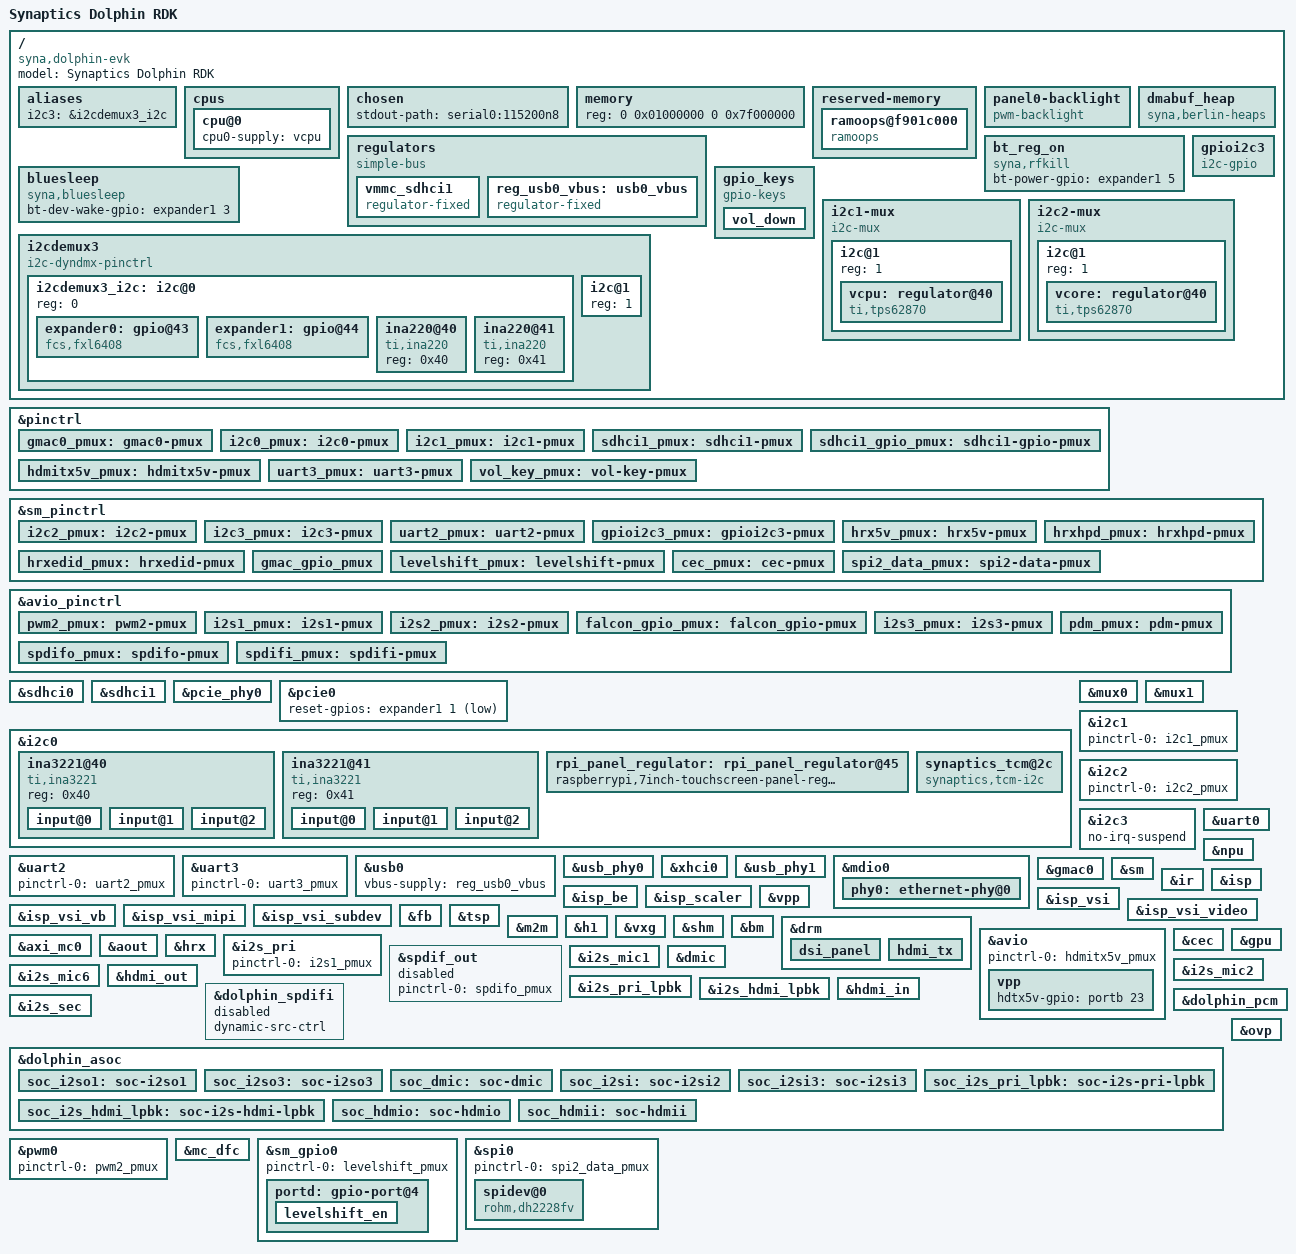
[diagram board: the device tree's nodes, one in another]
/* SPDX-License-Identifier: GPL-2.0+ */
/*
* Copyright (C) 2016~2023 Synaptics Incorporated. All rights reserved.
*
* This program is free software; you can redistribute it and/or modify
* it under the terms of the GNU General Public License version 2 or
* later as published by the Free Software Foundation.
*
* INFORMATION CONTAINED IN THIS DOCUMENT IS PROVIDED "AS-IS," AND
* SYNAPTICS EXPRESSLY DISCLAIMS ALL EXPRESS AND IMPLIED WARRANTIES,
* INCLUDING ANY IMPLIED WARRANTIES OF MERCHANTABILITY AND FITNESS FOR
* A PARTICULAR PURPOSE, AND ANY WARRANTIES OF NON-INFRINGEMENT OF ANY
* INTELLECTUAL PROPERTY RIGHTS. IN NO EVENT SHALL SYNAPTICS BE LIABLE
* FOR ANY DIRECT, INDIRECT, INCIDENTAL, SPECIAL, PUNITIVE, OR
* CONSEQUENTIAL DAMAGES ARISING OUT OF OR IN CONNECTION WITH THE USE
* OF THE INFORMATION CONTAINED IN THIS DOCUMENT, HOWEVER CAUSED AND
* BASED ON ANY THEORY OF LIABILITY, WHETHER IN AN ACTION OF CONTRACT,
* NEGLIGENCE OR OTHER TORTIOUS ACTION, AND EVEN IF SYNAPTICS WAS
* ADVISED OF THE POSSIBILITY OF SUCH DAMAGE. IF A TRIBUNAL OF
* COMPETENT JURISDICTION DOES NOT PERMIT THE DISCLAIMER OF DIRECT
* DAMAGES OR ANY OTHER DAMAGES, SYNAPTICS' TOTAL CUMULATIVE LIABILITY
* TO ANY PARTY SHALL NOT EXCEED ONE HUNDRED U.S. DOLLARS.
*/

/dts-v1/;

/memreserve/ 0x7f000000 0x01000000;

#include <dt-bindings/gpio/gpio.h>
#include <dt-bindings/input/linux-event-codes.h>

#include "dolphin.dtsi"

/ {
	model = "Synaptics Dolphin RDK";
	compatible = "syna,dolphin-evk", "syna,dolphin";

	aliases {
		i2c3 = &i2cdemux3_i2c;
	};

	cpus {
		cpu@0 {
			cpu0-supply = <&vcpu>;
		};
	};

	chosen {
		stdout-path = "serial0:115200n8";
	};

	memory {
		device_type = "memory";
		reg = <0 0x01000000 0 0x7f000000>;
	};

	reserved-memory {
		#address-cells = <2>;
		#size-cells = <2>;
		ranges;

		ramoops@f901c000{
			compatible = "ramoops";
			reg = <0x0 0xf901c000 0x0 0x4000>;
			record-size = <0x4000>;
		};
	};

	panel0-backlight {
		compatible = "pwm-backlight";
		pwms = <&pwm0 1 1000000 0>;
		brightness-levels = <0 4 8 16 32 64 128 255>;
		default-brightness-level = <6>;
		enable-gpio = <&expander0 1 GPIO_ACTIVE_HIGH>;
		status = "okay";
	};

	dmabuf_heap {
		compatible = "syna,berlin-heaps";
		pool-num = <2>;
		reg-names = "NonSecure", "Secure";
		reg = <0 0x7f000000 0 0x00800000>,
		      <0 0x7f800000 0 0x00800000>;
		attributes-num-per-pool = <2>;
		pool-attributes = <0x00000105 0x00000F3A 0x00000102 0x00000F3D>;
	};

	regulators {
		compatible = "simple-bus";
		#address-cells = <1>;
		#size-cells = <0>;

		vmmc_sdhci1: vmmc_sdhci1 {
			compatible = "regulator-fixed";
			regulator-min-microvolt = <3300000>;
			regulator-max-microvolt = <3300000>;
			regulator-name = "vmmc_sdio";
			enable-active-high;
			gpio = <&portb 12 GPIO_ACTIVE_HIGH>;
		};

		reg_usb0_vbus: usb0_vbus {
			compatible = "regulator-fixed";
			regulator-name = "usb0_vbus";
			regulator-min-microvolt = <5000000>;
			regulator-max-microvolt = <5000000>;
			gpio = <&expander0 5 GPIO_ACTIVE_HIGH>;
			enable-active-high;
		};
	};

	bt_reg_on: bt_reg_on {
		compatible = "syna,rfkill";
		bt-power-gpio = <&expander1 5 GPIO_ACTIVE_HIGH>;
	};

	bluesleep: bluesleep {
		compatible = "syna,bluesleep";
		bt-dev-wake-gpio = <&expander1 3 GPIO_ACTIVE_HIGH>;
	};

	gpio_keys {
		compatible = "gpio-keys";
		label = "gpio-keys";
		pinctrl-names = "default";
		pinctrl-0 = <&vol_key_pmux>;

		/* volume_up 已移除：它占用 portb6(pad STS1_SOP = J32 pin32)，
		 * 而本板把 J32.32 接到 TD7800 面板的 TP_RST。键被 gpio-keys 配成
		 * 输入+中断 → TP_RST 浮空 → 触摸芯片一直处于复位/未定义态。
		 * 本项目音量由语音控制，实体键无用。vol_down 保留。
		 */

		vol_down {
			label = "volume_down";
			gpio = <&portb 7 GPIO_ACTIVE_HIGH>;
			linux,code = <KEY_VOLUMEDOWN>;
			linux,can-disable;
			debounce-interval = <15>;
		};
	};

	gpioi2c3: gpioi2c3 {
		#address-cells = <1>;
		#size-cells = <0>;
		compatible = "i2c-gpio";
		gpios = <&portd 10 GPIO_ACTIVE_HIGH /* sda */
			 &portd 9 GPIO_ACTIVE_HIGH /* scl */
			>;
		i2c-gpio,delay-us = <5>;
	};

	i2c1-mux {
		compatible = "i2c-mux";
		i2c-parent = <&i2c1>;
		mux-controls = <&mux0 0>;
		#address-cells = <1>;
		#size-cells = <0>;

		i2c@1 {
			reg = <1>;
			#address-cells = <1>;
			#size-cells = <0>;

			vcpu: regulator@40 {
				compatible = "ti,tps62870";
				reg = <0x40>;
				status = "okay";
				regulator-boot-on;
				regulator-always-on;
				regulator-active-discharge = <0>;
				regulator-name = "vcpu";
				regulator-min-microvolt = <700000>;
				regulator-max-microvolt = <987500>;
			};
		};
	};

	i2c2-mux {
		compatible = "i2c-mux";
		i2c-parent = <&i2c2>;
		mux-controls = <&mux1 0>;
		#address-cells = <1>;
		#size-cells = <0>;

		i2c@1 {
			reg = <1>;
			#address-cells = <1>;
			#size-cells = <0>;

			vcore: regulator@40 {
				compatible = "ti,tps62870";
				reg = <0x40>;
				status = "okay";
				regulator-boot-on;
				regulator-always-on;
				regulator-active-discharge = <0>;
				regulator-name = "vcore";
				regulator-min-microvolt = <700000>;
				regulator-max-microvolt = <987500>;
			};
		};
	};

	i2cdemux3 {
		compatible = "i2c-dyndmx-pinctrl";
		#address-cells = <1>;
		#size-cells = <0>;

		i2c-parent = <&i2c3>, <&gpioi2c3>;

		pinctrl-names = "i2c3", "gpioi2c3";
		pinctrl-0 = <&i2c3_pmux>;
		pinctrl-1 = <&gpioi2c3_pmux>;

		i2cdemux3_i2c: i2c@0 {
			reg = <0>;
			#address-cells = <1>;
			#size-cells = <0>;

			expander0: gpio@43 {
				compatible = "fcs,fxl6408";
				reg = <0x43>;
				gpio-controller;
				#gpio-cells = <2>;
			};

			expander1: gpio@44 {
				compatible = "fcs,fxl6408";
				reg = <0x44>;
				gpio-controller;
				#gpio-cells = <2>;
			};

			ina220@40 {
				compatible = "ti,ina220";
				reg = <0x40>;
			};

			ina220@41 {
				compatible = "ti,ina220";
				reg = <0x41>;
			};
		};

		i2c@1 {
			reg = <1>;
			#address-cells = <1>;
			#size-cells = <0>;
		};
	};
};

&pinctrl {
	gmac0_pmux: gmac0-pmux {
		groups = "RGMII_MDC", "RGMII_MDIO", "RGMII_TXC", "RGMII_TXD0", "RGMII_TXD1", "RGMII_TXD2", "RGMII_TXD3", "RGMII_TXCTL", "RGMII_RXC", "RGMII_RXD0", "RGMII_RXD1", "RGMII_RXD2", "RGMII_RXD3", "RGMII_RXCTL";
		function = "rgmii";
		drive-strength = <3>;
	};

	i2c0_pmux: i2c0-pmux {
		groups = "TW0_SCL", "TW0_SDA";
		function = "tw0";
		drive-strength = <7>;
	};

	i2c1_pmux: i2c1-pmux {
		groups = "SPI1_SS2n", "SPI1_SS3n";
		function = "tw1b";
		drive-strength = <3>;
	};

	sdhci1_pmux: sdhci1-pmux {
		groups = "SDIO_CDn";
		function = "sdio";
		drive-strength = <7>;
	};

	sdhci1_gpio_pmux: sdhci1-gpio-pmux {
		groups = "SDIO_WP";
		function = "gpio";
	};

	hdmitx5v_pmux: hdmitx5v-pmux {
		groups = "USB2_DRV_VBUS";
		function = "gpio";
	};
	uart3_pmux: uart3-pmux {
		groups = "STS0_CLK", "STS0_SOP", "STS0_SD", "STS0_VALD";
		function = "uart3";
		drive-strength = <3>;
	};

	vol_key_pmux: vol-key-pmux {
		/* STS1_SOP  = GPIO38 = J32.32 = 面板 TP_RST   (下方 gpio-hog 常拉高)
		 * STS1_VALD = GPIO36 = J32.33 = 面板 LCD_RESET(交给 vpp 的 mipirst)
		 * STS1_CLK  = GPIO39 = vol_down
		 * 三个 pad 都要复用成 gpio；本组由 gpio_keys 节点在早期应用。 */
		groups = "STS1_SOP", "STS1_VALD", "STS1_CLK";
		function = "gpio";
	};
};

&sm_pinctrl {
	i2c2_pmux: i2c2-pmux {
		groups = "SM_URT1_TXD", "SM_URT1_RXD";
		function = "tw2b";
		drive-strength = <7>;
	};

	i2c3_pmux: i2c3-pmux {
		groups = "SM_TW3_SCL", "SM_TW3_SDA";
		function = "tw3";
		drive-strength = <7>;
	};

	uart2_pmux: uart2-pmux {
		groups = "SM_SPI2_SS2n", "SM_SPI2_SS3n", "SM_SPI2_SDI", "SM_SPI2_SDO";
		function = "uart2";
		drive-strength = <3>;
	};

	gpioi2c3_pmux: gpioi2c3-pmux {
		groups = "SM_TW3_SCL", "SM_TW3_SDA";
		function = "gpio";
		drive-strength = <7>;
	};

	hrx5v_pmux: hrx5v-pmux {
		groups = "SM_HDMIRX_PWR5V";
		function = "gpio";
		drive-strength = <7>;
	};

	hrxhpd_pmux: hrxhpd-pmux {
		groups = "SM_HDMI_HPD";
		function = "gpio";
	};

	hrxedid_pmux: hrxedid-pmux {
		groups = "SM_TW2_SCL", "SM_TW2_SDA";
		function = "rx_edid";
		drive-strength = <7>;
	};

	gmac_gpio_pmux: gmac_gpio_pmux {
		groups = "SM_TDO";
		function = "gpio";
	};

	levelshift_pmux: levelshift-pmux {
		groups = "SM_HDMIRX_HPD";
		function = "gpio";
	};

	cec_pmux: cec-pmux {
		groups = "SM_HDMI_CEC";
		function = "hdmi";
	};
};

&avio_pinctrl {
	pwm2_pmux: pwm2-pmux {
		groups = "I2S1_DO2";
		function = "pwm";
        };

	i2s1_pmux: i2s1-pmux {
		groups = "I2S1_BCLKIO", "I2S1_LRCKIO", "I2S1_DO0", "I2S1_MCLK";
		function = "i2s1";
	};

	i2s2_pmux: i2s2-pmux {
		groups = "I2S2_BCLKIO", "I2S2_LRCKIO", "I2S2_DI0";
		function = "i2s2";
	};

	falcon_gpio_pmux: falcon_gpio-pmux {
		groups = "I2S1_DO1";
		function = "gpio";
	};

	i2s3_pmux: i2s3-pmux {
		groups = "I2S3_LRCKIO", "I2S3_BCLKIO", "I2S3_DI", "I2S3_DO";
		function = "i2s3";
	};

	pdm_pmux: pdm-pmux {
		groups = "I2S2_MCLK", "I2S2_DI3", "I2S2_DI2";
		function = "pdm";
	};

	spdifo_pmux: spdifo-pmux {
		groups = "SPDIFO";
		function = "spdifo";
	};

	spdifi_pmux: spdifi-pmux {
		groups = "SPDIFI";
		function = "spdifi";
	};
};

&sdhci0 {
	status = "okay";
	sdclkdl-dc = /bits/ 8 <26>;
	mmc-ddr-1_8v;
	mmc-hs200-1_8v;
	mmc-hs400-1_8v;
	dll-calibration;
	pad-sp = /bits/ 8 <14>;
	pad-sn = /bits/ 8 <14>;
};

&sdhci1 {
	status = "okay";
	pinctrl-0 = <&sdhci1_pmux>, <&sdhci1_gpio_pmux>;
	pinctrl-names = "default";
	no-sdio;
	no-mmc;
	disable-wp;
	sdclkdl-dc = /bits/ 8 <75>;
	pad-sp = /bits/ 8 <4>;
	pad-sn = /bits/ 8 <4>;
	vmmc-supply = <&vmmc_sdhci1>;
};

&pcie_phy0 {
	status = "okay";
};

&pcie0 {
	status = "okay";
	reset-gpios = <&expander1 1 GPIO_ACTIVE_LOW>;
};

&i2c0 {
	status = "okay";
	pinctrl-names = "default";
	pinctrl-0 = <&i2c0_pmux>;
	no-irq-suspend;
	clock-frequency = <100000>;

	ina3221@40{
		compatible = "ti,ina3221";
		reg = <0x40>;
		#address-cells = <1>;
		#size-cells = <0>;

		input@0 {
			reg = <0x0>;
			label = "VCORE";
		};

		input@1 {
			reg = <0x1>;
			label = "VCPU";
		};

		input@2 {
			reg = <0x2>;
			label = "VDDM";
		};
	};

	ina3221@41{
		compatible = "ti,ina3221";
		reg = <0x41>;
		#address-cells = <1>;
		#size-cells = <0>;

		input@0 {
			reg = <0x0>;
			label = "PWR_3V3";
		};

		input@1 {
			reg = <0x1>;
			label = "VDDM_1V8";
		};

		input@2 {
			reg = <0x2>;
			label = "VDDM_1V1";
		};
	};

	rpi_panel_regulator: rpi_panel_regulator@45 {
		compatible = "raspberrypi,7inch-touchscreen-panel-regulator";
		reg = <0x45>;
		gpio-controller;
		#gpio-cells = <2>;
	};

	/* TD7800 TDDI touch (TM10.5 panel). TP I2C rides TW0 via J32.3/5.
	 * INT = TP_INT -> J32.12 = pad I2S2_DI1 func0 = GPIO10 = porta line 10
	 * (empirically confirmed: ATTN latches low, releases after I2C drain).
	 * NO reset-gpio on purpose: TDDI reset would kill the display; TP_RST
	 * and panel RESX are tied high in hardware.
	 * 0x2008 = IRQF_ONESHOT | IRQF_TRIGGER_LOW.
	 */
	synaptics_tcm@2c {
		compatible = "synaptics,tcm-i2c";
		reg = <0x2c>;
		status = "okay";
		interrupt-parent = <&porta>;
		interrupts = <10 0x2008>;
		synaptics,irq-gpio = <&porta 10 0x2008>;
		synaptics,irq-flags = <0x2008>;
		synaptics,irq-on-state = <0>;
		synaptics,power-delay-ms = <200>;
		synaptics,chunks = <1024 1024>;
		synaptics,command-timeout-ms = <3000>;
		synaptics,command-polling-ms = <20>;
		synaptics,command-turnaround-us = <50 100>;
		synaptics,command-retry-ms = <10>;
		synaptics,fw-switch-delay-ms = <100>;
	};
};

&mux0 {
	status = "okay";
};

&mux1 {
	status = "okay";
};

&i2c1 {
	status = "okay";
	pinctrl-names = "default";
	pinctrl-0 = <&i2c1_pmux>;
};

&i2c2 {
	status = "okay";
	pinctrl-names = "default";
	pinctrl-0 = <&i2c2_pmux>;
};

&i2c3 {
	status = "okay";
	no-irq-suspend;
};

&uart0 {
	status = "okay";
};

&uart2 {
	status = "okay";
	pinctrl-0 = <&uart2_pmux>;
	pinctrl-names = "default";
};

&uart3 {
	status = "okay";
	pinctrl-0 = <&uart3_pmux>;
	pinctrl-names = "default";
};

&npu {
	status = "okay";
};

&usb0 {
	vbus-supply = <&reg_usb0_vbus>;
	status = "okay";
};

&usb_phy0  {
	status = "okay";
};

&xhci0 {
	status = "okay";
};

&usb_phy1  {
	status = "okay";
};

&mdio0 {
	phy0: ethernet-phy@0 {
		reg = <0>;
		realtek,clkout-disable;
		realtek,rxc-ssc-enable;
		realtek,sysclk-ssc-enable;
	};
};

&gmac0 {
	status = "okay";
	pinctrl-0 = <&gmac0_pmux>, <&gmac_gpio_pmux>;
	pinctrl-names = "default";
	phy-handle = <&phy0>;
	phy-mode = "rgmii-id";
	snps,reset-gpio = <&portd 8 GPIO_ACTIVE_HIGH>;
	snps,reset-delays-us = <0 10000 50000>;
};

&sm {
	status = "okay";
};

&ir {
	status = "okay";
};

&isp {
	status = "okay";
	i2c-bus = <&i2c3>;
	dev-addr = <112>;
};

&isp_be {
	status = "okay";
};

&isp_scaler {
	status = "okay";
};

&vpp {
        status = "okay";
};

&isp_vsi {
	status = "okay";
	reset-gpios = <&expander1 0 0>, <&expander1 6 0>;
	enable-gpios = <&expander1 4 0>, <&expander1 7 0>;
};

&isp_vsi_video {
	status = "okay";
};

&isp_vsi_vb {
	status = "okay";
};

&isp_vsi_mipi {
	status = "okay";
};

&isp_vsi_subdev {
	status = "okay";
};

&fb {
	status = "okay";
};

&tsp {
	status = "okay";
};

&m2m {
	status = "okay";
};

&h1 {
	status = "okay";
};

&vxg {
	status = "okay";
};

&shm {
	status = "okay";
};

&bm {
	status = "okay";
};

&drm {
	status = "okay";

	/* Supported Modes:	0 - HDMI only
	 * 			1 - MIPI Only
	 *			2 - Dual Mode PIP
	 *
 	 * Supported types:	0 - HDMI
	 * 		  	3 - MIPI-DSI
	 */
	disp-mode = <2>;
	disp1-res-id = <61>;
	disp1-type = <0>;
	disp2-res-id = <102>;
	disp2-type = <3>;
	sw_partition = <14>;
	devnum = <0>;
	hw_partition = <0>; //0 - Default; 4 - 7 For GP1 to GP4

	dsi_panel {
		status= "okay";
		/* TM10.5 TD7800 10.5" 1280x720 LVDS panel via LAMTL adapter
		 * (Toshiba TC358775 DSI->LVDS). Native LVDS timing measured on
		 * Case44/RK3568: pclk 65.3MHz, H 1280/97/30/60, V 720/7/2/14.
		 * No power-supply/backlight phandles on purpose: adapter+panel
		 * power rides panel0-backlight (expander0.1 = PWR_ON_DSI).
		 */
		NO_OF_RESID =  <1>;
		DSI_RES =  <102>;
		ACTIVE_WIDTH = <1280>;
		HFP = <97>;
		HSYNCWIDTH = <30>;
		HBP = <60>;
		ACTIVE_HEIGHT = <720>;
		VFP = <7>;
		VSYNCWIDTH = <2>;
		VBP = <14>;
		TYPE = <1>;
		SCAN = <0>;
		FRAME_RATE = <9>;
		FLAG_3D = <0>;
		FREQ = <65300>;
		PTS_PER_4 = <6000>;

		bits_per_pixel = <24>;
		busformat = <0>;

		VB_MIN =  /bits/ 8 <6>;
		HB_MIN =  /bits/ 8 <30>;
		V_OFF = /bits/ 8 <6>;
		H_OFF = /bits/ 8 <20>;
		HB_VOP_OFF = /bits/ 8 <8>;
		VB_VOP_OFF = /bits/ 8 <3>;
		HB_BE = /bits/ 8 <7>;
		VB_BE = /bits/ 8 <2>;
		VB_FP = /bits/ 8 <2>;
		HB_FP = /bits/ 8 <10>;
		PIXEL_CLOCK = <65300>;

		HTOTAL = <1467>;
		Lanes = /bits/ 8 <4>;
		Vid_mode = /bits/ 8 <2>;
		virtual_chan = /bits/ 8 <0>;
		Clk_Lane_Polarity = /bits/ 8 <0>;
		Data_Lane_Polarity = /bits/ 8 <0>;
		Recv_ack = /bits/ 8 <0>;
		Loosely_18 = /bits/ 8 <0>;
		H_polarity = /bits/ 8 <1>;
		V_Polarity = /bits/ 8 <1>;
		Data_Polarity = /bits/ 8 <1>;
		Eotp_tx = /bits/ 8 <1>;
		Eotp_rx = /bits/ 8 <0>;
		non-Continuous_clk = /bits/ 8 <0>;
		dpi_lp_cmd =  /bits/ 8 <1>;
		Color_coding = /bits/ 8 <5>;
		Chunks = <0>;
		Null_Pkt = <0>;
		Byte_clk = <65300>;	/* DSIclk 261.2MHz: 带宽+33%余量, LVDS pclk=261.2/4=65.3MHz */

	/* TC358775 init over DSI generic long writes (0x29), addr+data LE.
	 * Source: LAMTL TC358775 timing XLS "Code" sheet; HTIM/VTIM/VPCTRL
	 * recomputed for 1280x720. Single-link on first link (OD/port-A):
	 * LVCFG=0x31 -> LVEN, PCLKDIV=3, LVDS pclk = 391.8MHz/6 = 65.3MHz.
	 * Color map = VESA 24bit (datasheet p39 values); if colors wrong,
	 * drop the seven 0x048x writes to fall back to JEIDA default.
	 * 0xFF <u32> = delay in us.
	 */
		command = /bits/ 8 <0x29 0x06 0x3C 0x01 0x05 0x00 0x03 0x00
			0x29 0x06 0x14 0x01 0x03 0x00 0x00 0x00
			0x29 0x06 0x64 0x01 0x04 0x00 0x00 0x00
			0x29 0x06 0x68 0x01 0x04 0x00 0x00 0x00
			0x29 0x06 0x6C 0x01 0x04 0x00 0x00 0x00
			0x29 0x06 0x70 0x01 0x04 0x00 0x00 0x00
			0x29 0x06 0x34 0x01 0x1F 0x00 0x00 0x00
			0x29 0x06 0x10 0x02 0x1F 0x00 0x00 0x00
			0x29 0x06 0x04 0x01 0x01 0x00 0x00 0x00
			0x29 0x06 0x04 0x02 0x01 0x00 0x00 0x00
			0x29 0x06 0x50 0x04 0x00 0x01 0xF0 0x03
			0x29 0x06 0x54 0x04 0x1E 0x00 0x3C 0x00
			0x29 0x06 0x58 0x04 0x00 0x05 0x61 0x00
			0x29 0x06 0x5C 0x04 0x02 0x00 0x0E 0x00
			0x29 0x06 0x60 0x04 0xD0 0x02 0x07 0x00
			0x29 0x06 0x64 0x04 0x01 0x00 0x00 0x00
			0x29 0x06 0xA0 0x04 0x06 0x80 0x44 0x00
			0xFF 0x64 0x00 0x00 0x00
			0x29 0x06 0xA0 0x04 0x06 0x80 0x04 0x00
			0x29 0x06 0x04 0x05 0x04 0x00 0x00 0x00
			0x29 0x06 0x80 0x04 0x00 0x01 0x02 0x03
			0x29 0x06 0x84 0x04 0x04 0x07 0x05 0x08
			0x29 0x06 0x88 0x04 0x09 0x0A 0x0E 0x0F
			0x29 0x06 0x8C 0x04 0x0B 0x0C 0x0D 0x10
			0x29 0x06 0x90 0x04 0x16 0x17 0x11 0x12
			0x29 0x06 0x94 0x04 0x13 0x14 0x15 0x1B
			0x29 0x06 0x98 0x04 0x18 0x19 0x1A 0x06
			0x29 0x06 0x9C 0x04 0x41 0x00 0x00 0x00
			0xFF 0x10 0x27 0x00 0x00>;
	};

	hdmi_tx {
		status= "okay";
		/* HDMI_Tx core config array with fields as in below order -
		   HPD handling - 1:enable sink hotplug handling 0:disable sink hotplug handling
		   FixedModeset - 1:Enable mode config from within drm driver(on HPD), disable modeset interface to user
				  0:Expose user interface to set mode, don't control from within drm driver
		 */
		hdtx-core-config = /bits/ 8 <1 1>;
		/* Select format IDs enabled for profile. enter number of entries (inclusive) followed by entries <size, n1, n2..>
		   ID to res mapping as below
		   1280x720P30=10 1280x720P60=13
		   1920x1080P24=22 1920x1080P25=21 1920x1080P30=19 1920x1080P50=26 1920x1080P59.94=25 1920x1080P60=24
		   3840x2160P24=57 3840x2160P25=59 3840x2160P30=61 3840x2160P50=62 3840x2160P59.94=63 3840x2160P60=64
		   720x576P50=9 */
		hdtx-supported-formats = /bits/ 8 <14 10 13 22 21 19 26 25 24 61 62 63 64 9>;
	};
};

&avio {
	status = "okay";
	pinctrl-0 = <&hdmitx5v_pmux>;
	pinctrl-names = "default";
	vpp {
		hdtx5v-gpio = <&portb 23 GPIO_ACTIVE_HIGH>;
	};
};

&cec {
	pinctrl-0 = <&cec_pmux>;
	pinctrl-names = "default";
	hdmi-phandle = <&drm>;
	status = "okay";
};

&axi_mc0 {
	status = "okay";
};

&gpu {
	status = "okay";
};

&aout {
	status = "okay";
};

&hrx {
	status = "okay";
	pinctrl-0 = <&hrx5v_pmux>, <&hrxhpd_pmux>, <&hrxedid_pmux>;
	pinctrl-names = "default";
	hrxhpd-gpio = <&portd 2 GPIO_ACTIVE_HIGH>;
	hrx5v-gpio = <&portd 21 GPIO_ACTIVE_HIGH>;
};

&i2s_pri {
	status = "okay";
	pinctrl-0 = <&i2s1_pmux>;
	pinctrl-names = "default";
};

&spdif_out {
	status = "disabled";
	pinctrl-0 = <&spdifo_pmux>;
	pinctrl-names = "default";
};

&i2s_mic1 {
	status = "okay";
	pinctrl-0 = <&i2s2_pmux>;
	pinctrl-names = "default";
	intlmode;
};

&dmic {
	status = "okay";
	pinctrl-0 = <&pdm_pmux>;
	pinctrl-names = "default";
	pdm-type = <1>;
	pdm-clk-sel = <2>;
	ch-shift-check;
};

&i2s_mic2 {
	status = "okay";
	pinctrl-0 = <&i2s3_pmux>;
	pinctrl-names = "default";
	duplex;
	disablemicmute;
	sample-period = <16>;
};

&i2s_mic6 {
	status = "okay";
};

&i2s_pri_lpbk {
	status = "okay";
};

&i2s_hdmi_lpbk {
	status = "okay";
};

&hdmi_out {
	status = "okay";
};

&hdmi_in {
	status = "okay";
};

&dolphin_spdifi {
	status = "disabled";
	//pinctrl-0 = <&spdifi_pmux>;
	//pinctrl-names = "default";
	//gate-gpio = <&expander2 4 GPIO_ACTIVE_HIGH>;
	//enable-gpio = <&expander3 7 GPIO_ACTIVE_LOW>;
	dynamic-src-ctrl;
};

&dolphin_pcm {
	status = "okay";
};

&i2s_sec {
	status = "okay";
	pinctrl-0 = <&i2s3_pmux>;
	pinctrl-names = "default";
	duplex;
	sample-period = <16>;
};


&dolphin_asoc {
	status = "okay";

	soc_i2so1: soc-i2so1 {
		status = "okay";
		stream-name = "soc-i2so1";
		link-name = "soc-i2so1";
		format = "i2s";
		/* Note that bitclock-master & frame-master is no longer set,
		 * as the assignment of clock producers & consumers has changed
		 * in kernel 6.12. With the updated setting, the CPU DAI is
		 * is still clock & frame producer and the codec clock & frame
		 * consumer.
		 */
		continuous-clock;
		bitclock-inversion;
		frame-inversion;
		cpu-node = <&i2s_pri>;
		codec-name = "snd-soc-dummy";
		codec-dai-name = "snd-soc-dummy-dai";
		platform-node = <&dolphin_pcm>;
	};

	soc_i2so3: soc-i2so3 {
		status = "okay";
		stream-name = "soc-i2so3";
		link-name = "soc-i2so3";
		format = "dsp_b";
		bitclock-master;
		frame-master;
		cpu-node = <&i2s_sec>;
		codec-name = "snd-soc-dummy";
		codec-dai-name = "snd-soc-dummy-dai";
		platform-node = <&dolphin_pcm>;
	};

	soc_dmic: soc-dmic {
		status = "okay";
		stream-name = "soc-dmic";
		link-name = "soc-dmic";
		cpu-node = <&dmic>;
		codec-name = "snd-soc-dummy";
		codec-dai-name = "snd-soc-dummy-dai";
		platform-node = <&dolphin_pcm>;
	};

	soc_i2si: soc-i2si2 {
		status = "okay";
		stream-name = "soc-i2si2";
		link-name = "soc-i2si2";
		format = "i2s";
		cpu-node = <&i2s_mic1>;
		codec-name = "snd-soc-dummy";
		codec-dai-name = "snd-soc-dummy-dai";
		platform-node = <&dolphin_pcm>;
	};

	soc_i2si3: soc-i2si3 {
		status = "okay";
		stream-name = "btsco-in";
		link-name = "btsco-in";
		format = "dsp_b";
		continuous-clock;
		bitclock-master;
		frame-master;
		cpu-node = <&i2s_mic2>;
		codec-name = "snd-soc-dummy";
		codec-dai-name = "snd-soc-dummy-dai";
		platform-node = <&dolphin_pcm>;
	};

	soc_i2s_pri_lpbk: soc-i2s-pri-lpbk {
		status = "okay";
		stream-name = "soc-i2s-pri-lpbk";
		link-name = "soc-i2s-pri-lpbk";
		format = "i2s";
		cpu-node = <&i2s_pri_lpbk>;
		codec-name = "snd-soc-dummy";
		codec-dai-name = "snd-soc-dummy-dai";
		platform-node = <&dolphin_pcm>;
	};

	soc_i2s_hdmi_lpbk: soc-i2s-hdmi-lpbk {
		status = "okay";
		stream-name = "soc-i2s-hdmi-lpbk";
		link-name = "soc-i2s-hdmi-lpbk";
		format = "i2s";
		cpu-node = <&i2s_hdmi_lpbk>;
		codec-name = "snd-soc-dummy";
		codec-dai-name = "snd-soc-dummy-dai";
		platform-node = <&dolphin_pcm>;
	};

	soc_hdmio: soc-hdmio {
		status = "okay";
		stream-name = "soc-hdmio";
		link-name = "soc-hdmio";
		format = "i2s";
		cpu-node = <&hdmi_out>;
		codec-name = "snd-soc-dummy";
		codec-dai-name = "snd-soc-dummy-dai";
		platform-node = <&dolphin_pcm>;
	};

	soc_hdmii: soc-hdmii {
		status = "okay";
		stream-name = "soc-hdmii";
		link-name = "soc-hdmii";
		cpu-node = <&hdmi_in>;
		codec-name = "snd-soc-dummy";
		codec-dai-name = "snd-soc-dummy-dai";
		platform-node = <&dolphin_pcm>;
	};
};

&ovp {
	status = "okay";
};

&pwm0 {
	pinctrl-0 = <&pwm2_pmux>;
	pinctrl-names = "default";
	status = "okay";
};

&mc_dfc {
	status = "okay";
};

&sm_gpio0 {
	pinctrl-0 = <&levelshift_pmux>;
	pinctrl-names = "default";

	portd: gpio-port@4 {
		levelshift_en {
			gpio-hog;
			gpios = <20 GPIO_ACTIVE_HIGH>;
			output-low;
		};
	};
};

/* SM SPI2 out to J32 pins 19(SDO)/21(SDI)/23(CLK)/24(SS0n).
 * Pads default to spi2 function at reset - no pinmux node needed.
 * spidev for TD7800 display SPI bring-up (9-bit DCX frames from userspace).
 */
&spi0 {
	status = "okay";
	pinctrl-names = "default";
	pinctrl-0 = <&spi2_data_pmux>;
	spidev@0 {
		compatible = "rohm,dh2228fv";
		reg = <0>;
		spi-max-frequency = <1000000>;
	};
};

/* U-Boot leaves SM_SPI2_SDO/SDI muxed as uart2 RTS/CTS - reclaim for spi2.
 * SCLK/SS0n already default to spi2 (function 0).
 */
&sm_pinctrl {
	spi2_data_pmux: spi2-data-pmux {
		groups = "SM_SPI2_SDO", "SM_SPI2_SDI";
		function = "spi2";
	};
};

/* ─────────────────────────────────────────────────────────────
 * TD7800 面板 TP_RST（J32 pin32 = portb6 = GPIO38）
 * 用户硬件时序：3.3V 与 TP_RESET 同时上电 —— 这里用 gpio-hog 让内核
 * 在 GPIO 控制器 probe 时立即驱动高并独占，之后谁也改不了。
 * 参考 Case44(RK3568) 同款做法：TDDI 的复位脚不要交给触摸驱动管，
 * 否则显示初始化时它还没拉高 → 屏和触摸互相死锁。
 * ⚠ TD7800 是 TDDI：这根线复位的是整颗芯片(含显示驱动)。
 * ───────────────────────────────────────────────────────────── */
/* TD7800 复位脚已改为面板侧 3.3V 上拉，SoC 不再驱动（2026-07-28）
 *
 * 曾经在这里放过两个 gpio-hog：
 *   td7800_lcd_rst_hog  portb 4 = GPIO36 = pad STS1_VALD = J32.33 = 面板 RESET_N
 *   td7800_tp_rst_hog   portb 6 = GPIO38 = pad STS1_SOP  = J32.32 = 面板 TCH_RESET_N
 * 实测两条 pad 电平分别是 1.57V 和 2.28V，都落在 TD7800 的禁区里：
 *   datasheet Table 44 第6项——RESET_N / TCH_RESET_N 属 IOVCC 域；
 *   Table 50——IOVCC = 2.7~3.6V；Table 51——VIH1 = 0.70 x IOVCC（3.3V 时 >= 2.31V）。
 * 而 SL1680 这组 pad 是 1.8V 域，输出高最多 1.8V，物理上给不出 2.31V。
 * 2.28V = 1.8 + 0.48 = pad 上端 ESD 二极管压降，说明面板侧 3.3V 上拉在往回灌电流。
 * 结果：TDDI 停在不确定复位态——I2C 从机块能应答固件 ID，但触摸引擎不跑、ATTN 永不拉低。
 * 拔掉两根线后中断立刻从 0 跳到 2626，定性确认。
 *
 * 现在两根杜邦线已物理拔除，复位由面板自带的 3.3V 上拉负责（上电即释放）。
 * 显示侧的初始化由 TC358775 的 command 序列 + 面板 NVM 自初始化负责。
 *
 * 要恢复 SoC 控制复位，必须先加 1.8V->3.3V 电平转换（74LVC2T45 固定方向，
 * 或每线 2N7002 + 10k 上拉到 3.3V；不要用 TXB/TXS 自动方向器件）。
 * 装好后按 Table 57 做时序：上电复位低电平宽度 tRW1 >= 3ms，
 * LCD_RST 比 TP_RST 延后 10ms 释放。届时把 hog 换成受控 GPIO，别再用 hog。
 */
